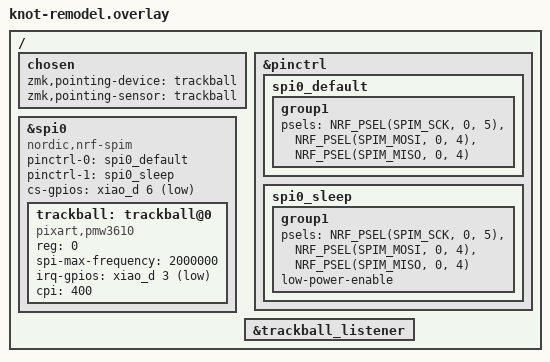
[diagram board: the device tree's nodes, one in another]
#include "knot-remodel.dtsi"

/ {
    chosen {
        zmk,pointing-device = <&trackball>;
        zmk,pointing-sensor = <&trackball>;
    };

    // あなたのピン設定は、あなたのハードウェアに合わせてあるので、完全に維持します
    &pinctrl {
        spi0_default: spi0_default {
            group1 {
                psels = <NRF_PSEL(SPIM_SCK, 0, 5)>,<NRF_PSEL(SPIM_MOSI, 0, 4)>,<NRF_PSEL(SPIM_MISO, 0, 4)>;
            };
        };
        spi0_sleep: spi0_sleep {
            group1 {
                psels = <NRF_PSEL(SPIM_SCK, 0, 5)>,<NRF_PSEL(SPIM_MOSI, 0, 4)>,<NRF_PSEL(SPIM_MISO, 0, 4)>;
                low-power-enable;
            };
        };
    };

    // あなたのSPIバスとセンサーのハードウェア定義を維持します
    &spi0 {
        status = "okay";
        compatible = "nordic,nrf-spim";
        pinctrl-0 = <&spi0_default>;
        pinctrl-1 = <&spi0_sleep>;
        pinctrl-names = "default", "sleep";
        cs-gpios = <&xiao_d 6 GPIO_ACTIVE_LOW>;

        trackball: trackball@0 {
            compatible = "pixart,pmw3610";
            reg = <0>;
            status = "okay";
            spi-max-frequency = <2000000>;
            irq-gpios = <&xiao_d 3 (GPIO_ACTIVE_LOW | GPIO_PULL_UP)>;
            cpi = <400>;
        };
    };

    // .dtsi ファイルで定義したトラックボールの基本機能を有効化します
    &trackball_listener {
        status = "okay";
    };
};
